# PAC55XX register map
Vendor: Active-Semi; Series: PAC55XX; File version: 1.0
CPU: CM4 r0p1, little endian, MPU, FPU, vendor SysTick, 3 interrupt priority bits
Registers are 32-bit, read-write, reset 0x0 unless marked. A register's access mark holds for its fields unless they carry their own. Offsets are from the block's base; [hi:lo] are bit positions; {n}, {i} and the like mark numbered series.

## SCC — System and Clock Control
Base 0x400D0400
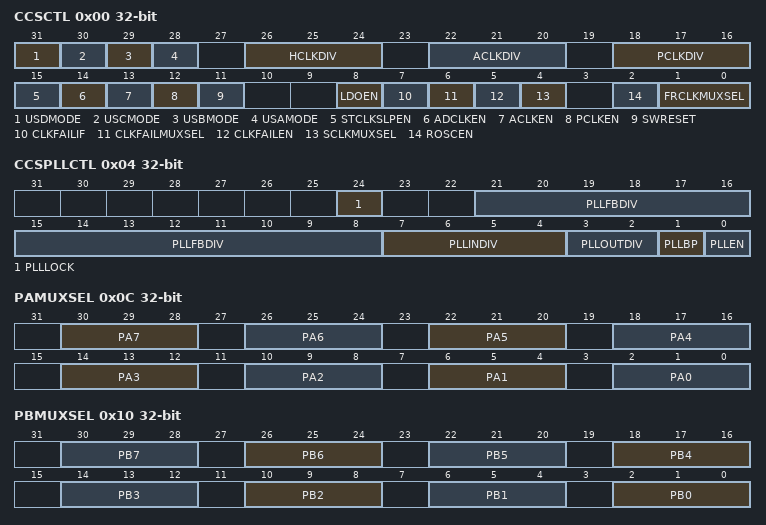
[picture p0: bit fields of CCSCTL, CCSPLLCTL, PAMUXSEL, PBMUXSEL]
0x00 CCSCTL
  [31] USDMODE — USART D Mode
    0=SSP (SSP Mode); 1=UART (UART Mode)
  [30] USCMODE — USART C Mode
    0=SSP (SSP Mode); 1=UART (UART Mode)
  [29] USBMODE — USART B Mode
    0=SSP (SSP Mode); 1=UART (UART Mode)
  [28] USAMODE — USART A Mode
    0=SSP (SSP Mode); 1=UART (UART Mode)
  [26:24] HCLKDIV — HCLK Divider
    {v}=SCLK /{v+1} (HCLK) (v=0..7)
  [22:20] ACLKDIV — ACLK Divider
    {v}=SCLK /{v+1} (ACLK) (v=0..7)
  [18:16] PCLKDIV — PCLK Divider
    {v}=HCLK /{v+1} (PCLK) (v=0..7)
  [15] STCLKSLPEN — SysTick Clock Sleep Enable
    0=Disabled (SysTick clock active in deep sleep); 1=Enabled (SysTick clock gated in deep sleep)
  [14] ADCLKEN — ADCCLK Enable
    0=Disabled (ADCCLK Disabled); 1=Enabled (ADCCLK Enabled)
  [13] ACLKEN — ACLK Enable
    0=Disabled (ACLK Disabled); 1=Enabled (ACLK Enabled)
  [12] PCLKEN — PCLK Enable
    0=Disabled (PCLK Disabled); 1=Enabled (PCLK Enabled)
  [11] SWRESET — Software Reset
    0=Not Reset (SW Reset Not Initiated); 1=Reset (SW Reset Initiated)
  [8] LDOEN — 1.8V LDO Enable
    0=Disabled (1.8V LDO Disabled); 1=Enabled (1.8V LDO Enabled)
  [7] CLKFAILIF — Clock Fail Interrupt Flag
    0=Not Set (Int Flag Not Set); 1=Set (Int Flag Set)
  [6] CLKFAILMUXSEL — Clock Fail Mux Select
    0=FRCLK (FRCLK selected as input to Clock Fail); 1=PLLCLK (PLLCLK selected as input to Clock Fail)
  [5] CLKFAILEN — Clock Fail Enable
    0=Disabled (Clock Fail Disabled); 1=Enabled (Clock Fail Enabled)
  [4] SCLKMUXSEL — SCLK Mux Select
    0=FRCLK (FRCLK selected as input to SCLK); 1=PLLCLK (PLLCLK selected as input to SCLK)
  [2] ROSCEN — ROSC Enable
    0=Disabled (ROSC Disabled); 1=Enabled (ROSC Enabled)
  [1:0] FRCLKMUXSEL — FRCLK MUX Select
    0=ROSC (ROSC selected as input to FRCLK); 1=CLKREF (CLKREF selected as input to FRCLK); 3=EXTCLK (External Clock selected as input to FRCLK)
0x04 CCSPLLCTL
  [24] PLLLOCK — PLL Lock Status
    0=Not Locked (PLL is not locked); 1=Locked (PLL is locked)
  [21:8] PLLFBDIV — PLL Feedback Divider
  [7:4] PLLINDIV — PLL Input Divider
  [3:2] PLLOUTDIV — PLL Output Divider
    {v}=/{v+1} (PLL output divided by {v+1}) (v=0..3)
  [1] PLLBP — PLL Bypass
    0=Inactive (PLL is not bypassed); 1=Active (PLL is bypassed)
  [0] PLLEN — PLL Enable
    0=Disabled (PLL Disabled); 1=Enabled (PLL Enabled)
0x08 CCSROSCTRIM
0x0C PAMUXSEL — PA Peripheral MUX Select
  [30:28] PA7 — PA7 MUX Select
    0=GPIOA7 (GPIO selected)
  [26:24] PA6 — PA6 MUX Select
    0=GPIOA6 (GPIO selected); 1=USASS (USART A SPI Slave Select); 2=USBSS (USART B SPI Slave Select)
  [22:20] PA5 — PA5 MUX Select
    0=GPIOA5 (GPIO selected); 1=USAMISO (USART A MISO/RX Selected); 2=USBMISO (USART B MISO/RX Selected)
  [18:16] PA4 — PA4 MUX Select
    0=GPIOA4 (GPIO selected); 1=USAMOSI (USART A MOSI/TX Selected); 2=USBMOSI (USART B MOSI/TX Selected)
  [14:12] PA3 — PA3 MUX Select
    0=GPIOA3 (GPIO selected); 1=USASCLK (USART A SCLK Selected); 2=USBSCLK (USART B SCLK Selected)
  [10:8] PA2 — PA2 MUX Select
    0=GPIOA2 (GPIO selected); 1=EMUXC (EMUX Clock Selected)
  [6:4] PA1 — PA1 MUX Select
    0=GPIOA1 (GPIO selected); 1=EMUXD (EMUX Data Selected)
  [2:0] PA0 — PA0 MUX Select
    0=GPIOA0 (GPIO selected)
0x10 PBMUXSEL — PB Peripheral MUX Select
  [4n+2:4n] PB{n} (n=4..7) — PB{n} MUX Select
    0=GPIOB{n} (GPIO selected); 1=TAPWM{n} (Timer A PWM{n} Selected); 2=TBPWM{n} (Timer B PWM{n} Selected); 3=TCPWM{n-4} (Timer C PWM{n-4} Selected); 4=TCPWM{n} (Timer C PWM{n} Selected); 5=TDPWM{n} (Timer D PWM{n} Selected)
  [4n+2:4n] PB{n} (n=0..3) — PB{n} MUX Select
    0=GPIOB{n} (GPIO selected); 1=TAPWM{n} (Timer A PWM{n} Selected); 2=TBPWM{n} (Timer B PWM{n} Selected); 4=TCPWM{n} (Timer C PWM{n} Selected); 5=TDPWM{n} (Timer D PWM{n} Selected)
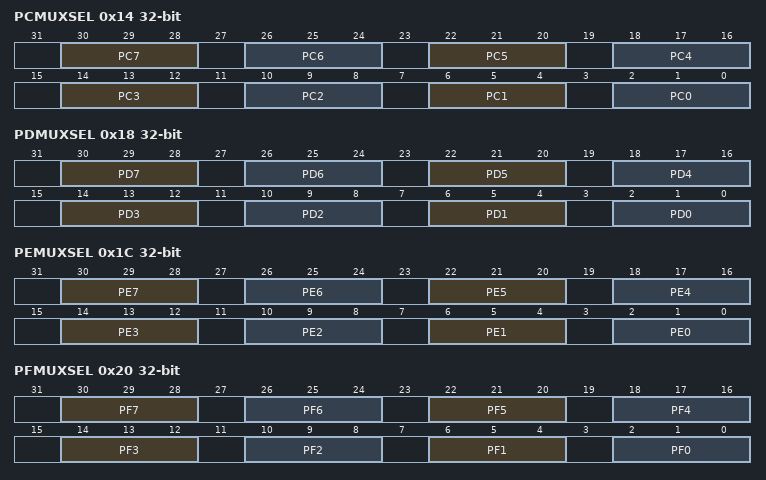
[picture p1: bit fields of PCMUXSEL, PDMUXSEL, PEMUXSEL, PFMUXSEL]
0x14 PCMUXSEL — PC Peripheral MUX Select
  [30:28] PC7 — PC7 MUX Select
    0=GPIOC7 (GPIO selected); 1=TBPWM7 (Timer B PWM7 Selected); 2=TCPWM7 (Timer C PWM7 Selected); 4=USBSS (USART B Slave Select Selected); 5=USCMISO (USART C MISO/RX Selected); 6=FRCLK (FRCLK Output Selected); 7=EMUXC (EMUX Clock Selected)
  [26:24] PC6 — PC6 MUX Select
    0=GPIOC6 (GPIO selected); 1=TBPWM6 (Timer B PWM6 Selected); 2=TCPWM6 (Timer C PWM6 Selected); 3=TCQEPPHB (Timer C QEP Phase B Selected); 4=USBSCLK (USART B SCLK Selected); 5=USCMOSI (USART C MOSI/TX Selected); 7=EMUXD (EMUX Data Selected)
  [22:20] PC5 — PC5 MUX Select
    0=GPIOC5 (GPIO selected); 1=TBPWM5 (Timer B PWM5 Selected); 2=TCPWM5 (Timer C PWM5 Selected); 3=TCQEPPHA (Timer C QEP Phase A Selected); 4=USBMISO (USART B MISO/RX Selected); 5=USCSS (USART C Slave Select Selected); 6=CANTXD (CAN Tx Data Selected); 7=I2CSDA (I2C SDA Selected)
  [18:16] PC4 — PC4 MUX Select
    0=GPIOC4 (GPIO selected); 1=TBPWM4 (Timer B PWM4 Selected); 2=TCPWM4 (Timer C PWM4 Selected); 3=TCQEPIDX (Timer C QEP Index Selected); 4=USBMOSI (USART B MOSI/TX Selected); 5=USCSCLK (USART C SPI Clock Selected); 6=CANRXD (CAN Rx Data Selected); 7=I2CSCL (I2C SCL Selected)
  [14:12] PC3 — PC3 MUX Select
    0=GPIOC3 (GPIO selected); 1=TBPWM3 (Timer B PWM3 Selected); 2=TCPWM3 (Timer C PWM3 Selected); 4=USBSS (USART B Slave Select Selected); 5=USCMISO (USART C MISO/RX Selected); 7=EMUXC (EMUX Clock Selected)
  [10:8] PC2 — PC2 MUX Select
    0=GPIOC2 (GPIO selected); 1=TBPWM2 (Timer B PWM2 Selected); 2=TCPWM2 (Timer C PWM2 Selected); 3=TBQEPPHB (Timer B QEP Phase B Selected); 4=USBSCLK (USART B SCLK Selected); 5=USCMOSI (USART C MOSI/TX Selected); 7=EMUXD (EMUX Data Selected)
  [6:4] PC1 — PC1 MUX Select
    0=GPIOC1 (GPIO selected); 1=TBPWM1 (Timer B PWM1 Selected); 2=TCPWM1 (Timer C PWM1 Selected); 3=TBQEPPHA (Timer B QEP Phase A Selected); 4=USBMISO (USART B MISO/RX Selected); 5=USCSS (USART C Slave Select Selected); 6=CANTXD (CAN Tx Data Selected); 7=I2CSDA (I2C SDA Selected)
  [2:0] PC0 — PC0 MUX Select
    0=GPIOC0 (GPIO selected); 1=TBPWM0 (Timer B PWM0 Selected); 2=TCPWM0 (Timer C PWM0 Selected); 3=TBQEPIDX (Timer B QEP Index Selected); 4=USBMOSI (USART B MOSI/TX Selected); 5=USCSCLK (USART C SPI Clock Selected); 6=CANRXD (CAN Rx Data Selected); 7=I2CSCL (I2C SCL Selected)
0x18 PDMUXSEL — PD Peripheral MUX Select
  [30:28] PD7 — PD7 MUX Select
    0=GPIOD7 (GPIO selected); 1=TBPWM7 (Timer B PWM7 Selected); 2=TCPWM7 (Timer C PWM7 Selected); 5=USDMISO (USART C MISO/RX Selected); 6=CANRXD (CAN Rx Data Selected); 7=I2CSCL (I2C SCL Selected)
  [26:24] PD6 — PD6 MUX Select
    0=GPIOD6 (GPIO selected); 1=TBPWM6 (Timer B PWM6 Selected); 2=TCPWM6 (Timer C PWM6 Selected); 3=TDQEPPHB (Timer D QEP Phase B Selected); 4=TBQEPPHB (Timer B QEP Phase B Selected); 5=USDMOSI (USART D MOSI/TX Selected); 6=CANTXD (CAN Tx Data Selected); 7=I2CSDA (I2C SDA Selected)
  [22:20] PD5 — PD5 MUX Select
    0=GPIOD5 (GPIO selected); 1=TBPWM5 (Timer B PWM5 Selected); 2=TCPWM5 (Timer C PWM5 Selected); 3=TDQEPPHA (Timer D QEP Phase A Selected); 4=TDQEPPHB (Timer D QEP Phase B Selected); 5=USDSCLK (USART D SPI Clock Selected); 6=CANRXD (CAN Rx Data Selected); 7=USDMISO (USART D MISO/RX Selected)
  [18:16] PD4 — PD4 MUX Select
    0=GPIOD4 (GPIO selected); 1=TBPWM4 (Timer B PWM4 Selected); 2=TCPWM4 (Timer C PWM4 Selected); 3=TDQEPIDX (Timer D QEP Index Selected); 4=TBQEPIDX (Timer B QEP Index Selected); 5=USDSCLK (USART D SPI Clock Selected); 6=TRACED3 (TRACE Data 3 output selected); 7=USDMOSI (USART D MOSI/TX Selected)
  [14:12] PD3 — PD3 MUX Select
    0=GPIOD3 (GPIO selected); 1=TBPWM3 (Timer B PWM3 Selected); 2=TCPWM3 (Timer C PWM3 Selected); 5=USCMISO (USART C MISO/RX Selected); 6=FRCLK (FRCLK output selected); 7=TRACED3 (TRACE Data 3 output selected)
  [10:8] PD2 — PD2 MUX Select
    0=GPIOD2 (GPIO selected); 1=TBPWM2 (Timer B PWM2 Selected); 2=TCPWM2 (Timer C PWM2 Selected); 3=TDQEPPHB (Timer D QEP Phase B Selected); 5=USCMOSI (USART C MOSI/TX Selected)
  [6:4] PD1 — PD1 MUX Select
    0=GPIOD1 (GPIO selected); 1=TBPWM1 (Timer B PWM1 Selected); 2=TCPWM1 (Timer C PWM1 Selected); 3=TDQEPPHA (Timer D QEP Phase A Selected); 5=USCSS (USART C Slave Select Selected); 6=CANRXD (CAN Rx Data Selected); 7=EMUXC (EMUX Clock Selected)
  [2:0] PD0 — PD0 MUX Select
    0=GPIOD0 (GPIO selected); 1=TBPWM0 (Timer B PWM0 Selected); 2=TCPWM0 (Timer C PWM0 Selected); 3=TDQEPIDX (Timer D QEP Index Selected); 5=USCSCLK (USART C SPI Clock Selected); 6=CANTXD (CAN Tx Data Selected); 7=EMUXD (EMUX Data Selected)
0x1C PEMUXSEL — PE Peripheral MUX Select
  [30:28] PE7 — PE7 MUX Select
    0=GPIOE7 (GPIO selected); 1=TCPWM7 (Timer C PWM7 Selected); 2=TDPWM7 (Timer D PWM7 Selected); 4=USBMISO (USART B MISO/RX Selected); 5=USDSS (USART D Slave Select Selected); 6=CANTXD (CAN TX Data Selected)
  [26:24] PE6 — PE6 MUX Select
    0=GPIOE6 (GPIO selected); 1=TCPWM6 (Timer C PWM6 Selected); 2=TDPWM6 (Timer D PWM6 Selected); 3=TDQEPPHB (Timer D QEP Phase B Selected); 4=USBMOSI (USART B MOSI/TX Selected); 5=USDSCLK (USART D SCLK Selected); 6=CANRXD (CAN RX Data Selected)
  [22:20] PE5 — PE5 MUX Select
    0=GPIOE5 (GPIO selected); 1=TCPWM5 (Timer C PWM5 Selected); 2=TDPWM5 (Timer D PWM5 Selected); 3=TDQEPPHA (Timer D QEP Phase A Selected); 4=USBSS (USART B Slave Select Selected); 5=USDMISO (USART D MISO/RX Selected); 6=I2CSDA (I2C SDA Selected)
  [18:16] PE4 — PE4 MUX Select
    0=GPIOE4 (GPIO selected); 1=TCPWM4 (Timer C PWM4 Selected); 2=TDPWM4 (Timer D PWM4 Selected); 3=TDQEPIDX (Timer D QEP Index Selected); 4=USBSCLK (USART B SCLK Selected); 5=USDMOSI (USART D MOSI/TX Selected); 6=I2CSCL (I2C SCL Selected)
  [14:12] PE3 — PE3 MUX Select
    0=GPIOE3 (GPIO selected); 1=TCPWM7 (Timer C PWM7 Selected); 2=TDPWM3 (Timer D PWM3 Selected); 3=FRCLK (FRCLK Output Selected); 5=USCMISO (USART C MISO/RX Selected); 6=CANTXD (CAN Tx Data Selected)
  [10:8] PE2 — PE2 MUX Select
    0=GPIOE2 (GPIO selected); 1=TCPWM6 (Timer C PWM6 Selected); 2=TDPWM2 (Timer D PWM2 Selected); 3=TAQEPPHB (Timer A QEP Phase B Selected); 4=TBQEPPHB (Timer B QEP Phase B Selected); 5=USCMOSI (USART C MOSI/TX Selected); 6=CANRXD (CAN Rx Data Selected); 7=EXTCLK (External clock input Selected)
  [6:4] PE1 — PE1 MUX Select
    0=GPIOE1 (GPIO selected); 1=TCPWM5 (Timer C PWM5 Selected); 2=TDPWM1 (Timer D PWM1 Selected); 3=TAQEPPHA (Timer A QEP Phase A Selected); 4=TBQEPPHA (Timer B QEP Phase A Selected); 5=USCSS (USART C Slave Select Selected); 6=I2CSDA (I2C SDA Selected); 7=EMUXD (EMUX Data Selected)
  [2:0] PE0 — PE0 MUX Select
    0=GPIOE0 (GPIO selected); 1=TCPWM4 (Timer C PWM4 Selected); 2=TDPWM0 (Timer D PWM0 Selected); 3=TAQEPIDX (Timer A QEP Index Selected); 4=TBQEPIDX (Timer B QEP Index Selected); 5=USCSCLK (USART C SPI Clock Selected); 6=I2CSCL (I2C SCL Selected); 7=EMUXC (EMUX Clock Selected)
0x20 PFMUXSEL — PF Peripheral MUX Select
  [30:28] PF7 — PF7 MUX Select
    0=GPIOF7 (GPIO selected); 1=TCPWM7 (Timer C PWM7 Selected); 2=TDPWM7 (Timer D PWM7 Selected); 5=USDMISO (USART D MISO/RX Selected); 6=CANTXD (CAN TX Data Selected); 7=I2CSDA (I2C SDA Selected)
  [26:24] PF6 — PF6 MUX Select
    0=GPIOF6 (GPIO selected); 1=TCPWM6 (Timer C PWM6 Selected); 2=TDPWM6 (Timer D PWM6 Selected); 4=TCQEPPHB (Timer C QEP Phase B Selected); 5=USDMOSI (USART D MOSI/TX Selected); 6=CANRXD (CAN RX Data Selected); 7=I2CSCL (I2C SCL Selected)
  [22:20] PF5 — PF5 MUX Select
    0=GPIOF5 (GPIO selected); 1=TCPWM5 (Timer C PWM5 Selected); 2=TDPWM5 (Timer D PWM5 Selected); 4=TCQEPPHA (Timer C QEP Phase A Selected); 5=USDSS (USART D Slave Select Selected); 7=EMUXD (EMUX Data Selected)
  [18:16] PF4 — PF4 MUX Select
    0=GPIOF4 (GPIO selected); 1=TCPWM4 (Timer C PWM4 Selected); 2=TDPWM4 (Timer D PWM4 Selected); 4=TCQEPIDX (Timer C QEP Index Selected); 5=USDSCLK (USART D SCLK Selected); 6=TRACED3 (TRACED3 Selected); 7=EMUXC (EMUX Clock Selected)
  [14:12] PF3 — PF3 MUX Select
    0=GPIOF3 (GPIO selected); 1=TCPWM3 (Timer C PWM3 Selected); 2=TDPWM3 (Timer D PWM3 Selected); 3=TDO (TDO Selected); 4=FRCLK (FRCLK Output Selected); 5=USBMISO (USART B MISO/RX Selected); 6=TRACECLK (TRACECLK Selected); 7=TRACED2 (TRACED2 Selected)
  [10:8] PF2 — PF2 MUX Select
    0=GPIOF2 (GPIO selected); 1=TCPWM2 (Timer C PWM2 Selected); 2=TDPWM2 (Timer D PWM2 Selected); 3=TDI (TDI Selected); 4=TBQEPPHB (Timer B QEP Phase B Selected); 5=USBMOSI (USART B MOSI/TX Selected); 6=TRACED0 (TRACED0 Selected); 7=TRACED1 (TRACED1 Selected)
  [6:4] PF1 — PF1 MUX Select
    0=GPIOF1 (GPIO selected); 1=TCPWM1 (Timer C PWM1 Selected); 2=TDPWM1 (Timer D PWM1 Selected); 3=TMS_SWDIO (TMS/SWDIO Selected); 4=TBQEPPHA (Timer B QEP Phase A Selected); 5=USBSS (USART B Slave Select Selected); 6=TRACED1 (TRACED1 Selected); 7=TRACED0 (TRACED0 Selected)
  [2:0] PF0 — PF0 MUX Select
    0=GPIOF0 (GPIO selected); 1=TCPWM0 (Timer C PWM0 Selected); 2=TDPWM0 (Timer D PWM0 Selected); 3=TCK_SWDCLK (TCK/SWDCLK Selected); 4=TBQEPIDX (Timer B QEP Index Selected); 5=USBSCLK (USART B SPI Clock Selected); 6=TRACED2 (TRACED2 Selected); 7=TRACECLK (TRACECLK Selected)
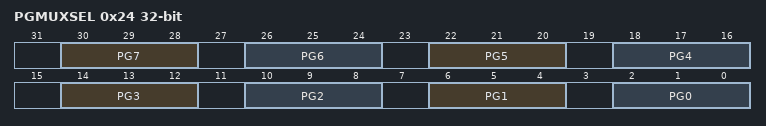
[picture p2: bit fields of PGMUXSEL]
0x24 PGMUXSEL — PG Peripheral MUX Select
  [30:28] PG7 — PG7 MUX Select
    0=GPIOG7 (GPIO selected); 2=TDQEPIDX (Timer D QEP Index Selected); 5=USDSCLK (USART D SPI Clock Selected)
  [26:24] PG6 — PG6 MUX Select
    0=GPIOG6 (GPIO selected); 1=TCPWM6 (Timer C PWM6 Selected); 2=TDPWM6 (Timer D PWM6 Selected); 3=I2CSDA (I2C SDA Selected); 5=USDMISO (USART D MISO/RX Selected); 6=CANTXD (CAN TX Data Selected); 7=TDQEPPHB (Timer D QEP Phase B)
  [22:20] PG5 — PG5 MUX Select
    0=GPIOG5 (GPIO selected); 1=TCPWM5 (Timer C PWM5 Selected); 2=TDPWM5 (Timer D PWM5 Selected); 3=EMUXC (EMUX Clock Selected); 5=USDMOSI (USART D MOSI/TX Selected); 6=CANRXD (CAN RX Data Selected); 7=TDQEPPHA (Timer D QEP Phase A Selected)
  [18:16] PG4 — PG4 MUX Select
    0=GPIOG4 (GPIO selected); 1=TCPWM4 (Timer C PWM4 Selected); 2=TDPWM4 (Timer D PWM4 Selected); 3=EMUXD (EMUX Data Selected); 4=I2CSCL (I2C SCL Selected); 5=USDSS (USART D Slave Select Selected); 6=TRACED3 (TRACED3 Selected); 7=TDQEPIDX (Timer D QEP Index Selected)
  [14:12] PG3 — PG3 MUX Select
    0=GPIOG3 (GPIO selected); 1=TCPWM3 (Timer C PWM3 Selected); 2=TDPWM3 (Timer D PWM3 Selected); 5=USDMISO (USART D MISO/RX Selected); 6=TRACED2 (TRACED2 Selected)
  [10:8] PG2 — PG2 MUX Select
    0=GPIOG2 (GPIO selected); 1=TCPWM2 (Timer C PWM2 Selected); 2=TDPWM2 (Timer D PWM2 Selected); 3=FRCLK (FRCLK Output Selected); 5=USDMOSI (USART D MOSI/TX Selected); 6=TRACED1 (TRACED1 Selected); 7=TCQEPPHB (Timer C QEP Phase B Selected)
  [6:4] PG1 — PG1 MUX Select
    0=GPIOG1 (GPIO selected); 1=TCPWM1 (Timer C PWM1 Selected); 2=TDPWM1 (Timer D PWM1 Selected); 3=EMUXD (EMUX Data Selected); 5=USDSS (USART D Slave Select Selected); 6=TRACED0 (TRACED0 Selected); 7=TCQEPPHA (Timer C QEP Phase A Selected)
  [2:0] PG0 — PG0 MUX Select
    0=GPIOG0 (GPIO selected); 1=TCPWM0 (Timer C PWM0 Selected); 2=TDPWM0 (Timer D PWM0 Selected); 3=EMUXC (EMUX Clock Selected); 5=USDSCLK (USART D SPI Clock Selected); 6=TRACECLK (TRACECLK Selected); 7=TCQEPIDX (Timer C QEP Index Selected)
0x28 PAPUEN — PA Weak Pull-up Enable
0x2C PBPUEN — PB Weak Pull-up Enable
0x30 PCPUEN — PC Weak Pull-up Enable
0x34 PDPUEN — PD Weak Pull-up Enable
0x38 PEPUEN — PE Weak Pull-up Enable
0x3C PFPUEN — PF Weak Pull-up Enable
0x40 PGPUEN — PG Weak Pull-up Enable
0x44 PAPDEN — PA Weak Pull-down Enable
0x48 PBPDEN — PB Weak Pull-down Enable
0x4C PCPDEN — PC Weak Pull-down Enable
0x50 PDPDEN — PD Weak Pull-down Enable
0x54 PEPDEN — PE Weak Pull-down Enable
0x58 PFPDEN — PF Weak Pull-down Enable
0x5C PGPDEN — PG Weak Pull-down Enable
0x60 PADS — PA Drive Strength/Schmitt Trigger
0x64 PBDS — PB Drive Strength/Schmitt Trigger
0x68 PCDS — PC Drive Strength/Schmitt Trigger
0x6C PDDS — PD Drive Strength/Schmitt Trigger
0x70 PEDS — PE Drive Strength/Schmitt Trigger
0x74 PFDS — PF Drive Strength/Schmitt Trigger
0x78 PGDS — PG Drive Strength/Schmitt Trigger
